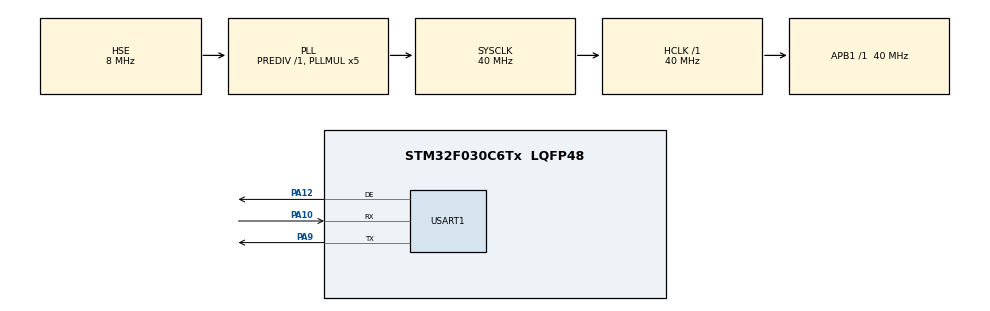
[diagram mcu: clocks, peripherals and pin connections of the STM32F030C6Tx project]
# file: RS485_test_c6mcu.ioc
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Dma.Request0=USART1_RX
Dma.USART1_RX.0.Direction=DMA_PERIPH_TO_MEMORY
Dma.USART1_RX.0.Instance=DMA1_Channel3
Dma.USART1_RX.0.MemDataAlignment=DMA_MDATAALIGN_BYTE
Dma.USART1_RX.0.MemInc=DMA_MINC_ENABLE
Dma.USART1_RX.0.Mode=DMA_NORMAL
Dma.USART1_RX.0.PeriphDataAlignment=DMA_PDATAALIGN_BYTE
Dma.USART1_RX.0.PeriphInc=DMA_PINC_DISABLE
Dma.USART1_RX.0.Priority=DMA_PRIORITY_LOW
Mcu.Family=STM32F0
Mcu.Name=STM32F030C6Tx
Mcu.Package=LQFP48
NVIC.DMA1_Channel2_3_IRQn=true\:0\:0\:false\:false\:true\:false
NVIC.USART1_IRQn=true\:0\:0\:false\:false\:true\:true
PA10.Mode=Asynchronous
PA10.Signal=USART1_RX
PA12.Mode=Hardware Flow Control (RS485)
PA12.Signal=USART1_DE
PA13.Mode=Serial_Wire
PA13.Signal=SYS_SWDIO
PA14.Mode=Serial_Wire
PA14.Signal=SYS_SWCLK
PA9.Mode=Asynchronous
PA9.Signal=USART1_TX
PF0-OSC_IN.Mode=HSE-External-Oscillator
PF0-OSC_IN.Signal=RCC_OSC_IN
PF1-OSC_OUT.Mode=HSE-External-Oscillator
PF1-OSC_OUT.Signal=RCC_OSC_OUT
ProjectManager.HeapSize=0x200
ProjectManager.StackSize=0x400
ProjectManager.TargetToolchain=MDK-ARM V5
RCC.AHBFreq_Value=40000000
RCC.APB1Freq_Value=40000000
RCC.APB1TimFreq_Value=40000000
RCC.HCLKFreq_Value=40000000
RCC.PLLMUL=RCC_PLL_MUL5
RCC.PLLSourceVirtual=RCC_PLLSOURCE_HSE
RCC.SYSCLKFreq_VALUE=40000000
RCC.SYSCLKSource=RCC_SYSCLKSOURCE_PLLCLK
USART1.UART_DEAssertionTime=10
USART1.UART_DEDeassertionTime=10
USART1.VirtualMode-Asynchronous=VM_ASYNC
USART1.VirtualMode-Hardware\ Flow\ Control\ (RS485)=VM_ASYNC
VP_TIM1_VS_ClockSourceINT.Mode=Internal
board=custom

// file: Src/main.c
/* USER CODE BEGIN Header */
/**
  ******************************************************************************
  * @file           : main.c
  * @brief          : Main program body
  ******************************************************************************
  ** This notice applies to any and all portions of this file
  * that are not between comment pairs USER CODE BEGIN and
  * USER CODE END. Other portions of this file, whether
  * inserted by the user or by software development tools
  * are owned by their respective copyright owners.
  *
  * COPYRIGHT(c) 2019 STMicroelectronics
  *
  * Redistribution and use in source and binary forms, with or without modification,
  * are permitted provided that the following conditions are met:
  *   1. Redistributions of source code must retain the above copyright notice,
  *      this list of conditions and the following disclaimer.
  *   2. Redistributions in binary form must reproduce the above copyright notice,
  *      this list of conditions and the following disclaimer in the documentation
  *      and/or other materials provided with the distribution.
  *   3. Neither the name of STMicroelectronics nor the names of its contributors
  *      may be used to endorse or promote products derived from this software
  *      without specific prior written permission.
  *
  * THIS SOFTWARE IS PROVIDED BY THE COPYRIGHT HOLDERS AND CONTRIBUTORS "AS IS"
  * AND ANY EXPRESS OR IMPLIED WARRANTIES, INCLUDING, BUT NOT LIMITED TO, THE
  * IMPLIED WARRANTIES OF MERCHANTABILITY AND FITNESS FOR A PARTICULAR PURPOSE ARE
  * DISCLAIMED. IN NO EVENT SHALL THE COPYRIGHT HOLDER OR CONTRIBUTORS BE LIABLE
  * FOR ANY DIRECT, INDIRECT, INCIDENTAL, SPECIAL, EXEMPLARY, OR CONSEQUENTIAL
  * DAMAGES (INCLUDING, BUT NOT LIMITED TO, PROCUREMENT OF SUBSTITUTE GOODS OR
  * SERVICES; LOSS OF USE, DATA, OR PROFITS; OR BUSINESS INTERRUPTION) HOWEVER
  * CAUSED AND ON ANY THEORY OF LIABILITY, WHETHER IN CONTRACT, STRICT LIABILITY,
  * OR TORT (INCLUDING NEGLIGENCE OR OTHERWISE) ARISING IN ANY WAY OUT OF THE USE
  * OF THIS SOFTWARE, EVEN IF ADVISED OF THE POSSIBILITY OF SUCH DAMAGE.
  *
  ******************************************************************************
  */
/* USER CODE END Header */

#include "main.h"
#include "stm32f0xx_hal.h"
#include "serialcomm.h"
#include "libModbus.h"

/* USER CODE BEGIN PD */
uint8_t rxBuffer[50];
/* USER CODE END PD */

TIM_HandleTypeDef htim1;

UART_HandleTypeDef huart1;
DMA_HandleTypeDef hdma_usart1_rx;

void SystemClock_Config(void);
static void MX_GPIO_Init(void);
static void MX_DMA_Init(void);
static void MX_USART1_UART_Init(void);
static void MX_TIM1_Init(void);

int main(void)
{

  /* MCU Configuration--------------------------------------------------------*/

  /* Reset of all peripherals, Initializes the Flash interface and the Systick. */
  HAL_Init();

  /* Configure the system clock */
  SystemClock_Config();

  /* Initialize all configured peripherals */
  MX_GPIO_Init();
  MX_DMA_Init();
  MX_USART1_UART_Init();
  MX_TIM1_Init();
	sercomm_init(&huart1, &hdma_usart1_rx);

  /* Infinite loop */
  /* USER CODE BEGIN WHILE */
  while (1)
  {

		ProcessPetitModbus();
    /* USER CODE END WHILE */

  }
}

void SystemClock_Config(void)
{
  RCC_OscInitTypeDef RCC_OscInitStruct = {0};
  RCC_ClkInitTypeDef RCC_ClkInitStruct = {0};
  RCC_PeriphCLKInitTypeDef PeriphClkInit = {0};

  /**Initializes the CPU, AHB and APB busses clocks
  */
  RCC_OscInitStruct.OscillatorType = RCC_OSCILLATORTYPE_HSE;
  RCC_OscInitStruct.HSEState = RCC_HSE_ON;
  RCC_OscInitStruct.PLL.PLLState = RCC_PLL_ON;
  RCC_OscInitStruct.PLL.PLLSource = RCC_PLLSOURCE_HSE;
  RCC_OscInitStruct.PLL.PLLMUL = RCC_PLL_MUL5;
  RCC_OscInitStruct.PLL.PREDIV = RCC_PREDIV_DIV1;
  if (HAL_RCC_OscConfig(&RCC_OscInitStruct) != HAL_OK)
  {
    Error_Handler();
  }
  /**Initializes the CPU, AHB and APB busses clocks
  */
  RCC_ClkInitStruct.ClockType = RCC_CLOCKTYPE_HCLK|RCC_CLOCKTYPE_SYSCLK
                              |RCC_CLOCKTYPE_PCLK1;
  RCC_ClkInitStruct.SYSCLKSource = RCC_SYSCLKSOURCE_PLLCLK;
  RCC_ClkInitStruct.AHBCLKDivider = RCC_SYSCLK_DIV1;
  RCC_ClkInitStruct.APB1CLKDivider = RCC_HCLK_DIV1;

  if (HAL_RCC_ClockConfig(&RCC_ClkInitStruct, FLASH_LATENCY_1) != HAL_OK)
  {
    Error_Handler();
  }
  PeriphClkInit.PeriphClockSelection = RCC_PERIPHCLK_USART1;
  PeriphClkInit.Usart1ClockSelection = RCC_USART1CLKSOURCE_PCLK1;
  if (HAL_RCCEx_PeriphCLKConfig(&PeriphClkInit) != HAL_OK)
  {
    Error_Handler();
  }
}

static void MX_TIM1_Init(void)
{

  TIM_ClockConfigTypeDef sClockSourceConfig = {0};
  TIM_MasterConfigTypeDef sMasterConfig = {0};

  htim1.Instance = TIM1;
  htim1.Init.Prescaler = 0;
  htim1.Init.CounterMode = TIM_COUNTERMODE_UP;
  htim1.Init.Period = 0;
  htim1.Init.ClockDivision = TIM_CLOCKDIVISION_DIV1;
  htim1.Init.RepetitionCounter = 0;
  htim1.Init.AutoReloadPreload = TIM_AUTORELOAD_PRELOAD_DISABLE;
  if (HAL_TIM_Base_Init(&htim1) != HAL_OK)
  {
    Error_Handler();
  }
  sClockSourceConfig.ClockSource = TIM_CLOCKSOURCE_INTERNAL;
  if (HAL_TIM_ConfigClockSource(&htim1, &sClockSourceConfig) != HAL_OK)
  {
    Error_Handler();
  }
  sMasterConfig.MasterOutputTrigger = TIM_TRGO_RESET;
  sMasterConfig.MasterSlaveMode = TIM_MASTERSLAVEMODE_DISABLE;
  if (HAL_TIMEx_MasterConfigSynchronization(&htim1, &sMasterConfig) != HAL_OK)
  {
    Error_Handler();
  }

}

static void MX_USART1_UART_Init(void)
{

  huart1.Instance = USART1;
  huart1.Init.BaudRate = 9600;
  huart1.Init.WordLength = UART_WORDLENGTH_8B;
  huart1.Init.StopBits = UART_STOPBITS_1;
  huart1.Init.Parity = UART_PARITY_NONE;
  huart1.Init.Mode = UART_MODE_TX_RX;
  huart1.Init.HwFlowCtl = UART_HWCONTROL_NONE;
  huart1.Init.OverSampling = UART_OVERSAMPLING_16;
  huart1.Init.OneBitSampling = UART_ONE_BIT_SAMPLE_DISABLE;
  huart1.AdvancedInit.AdvFeatureInit = UART_ADVFEATURE_NO_INIT;
  if (HAL_RS485Ex_Init(&huart1, UART_DE_POLARITY_HIGH, 10, 10) != HAL_OK)
  {
    Error_Handler();
  }

}

static void MX_DMA_Init(void)
{
  /* DMA controller clock enable */
  __HAL_RCC_DMA1_CLK_ENABLE();

  /* DMA interrupt init */
  /* DMA1_Channel2_3_IRQn interrupt configuration */
  HAL_NVIC_SetPriority(DMA1_Channel2_3_IRQn, 0, 0);
  HAL_NVIC_EnableIRQ(DMA1_Channel2_3_IRQn);

}

static void MX_GPIO_Init(void)
{

  /* GPIO Ports Clock Enable */
  __HAL_RCC_GPIOF_CLK_ENABLE();
  __HAL_RCC_GPIOA_CLK_ENABLE();

}

void Error_Handler(void)
{
}

/************************ (C) COPYRIGHT STMicroelectronics *****END OF FILE****/
